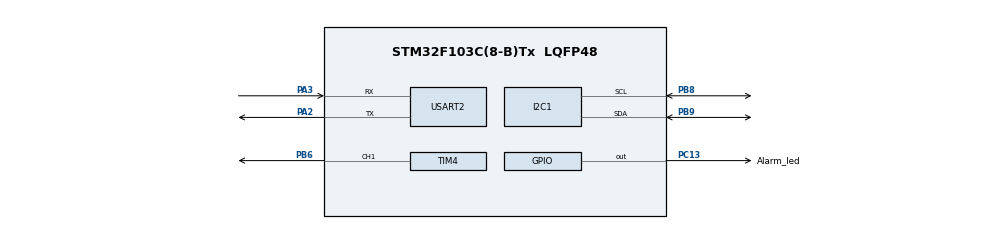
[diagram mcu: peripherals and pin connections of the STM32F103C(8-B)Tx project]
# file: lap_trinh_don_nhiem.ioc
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Dma.Request0=USART2_RX
Dma.USART2_RX.0.Direction=DMA_PERIPH_TO_MEMORY
Dma.USART2_RX.0.Instance=DMA1_Channel6
Dma.USART2_RX.0.MemDataAlignment=DMA_MDATAALIGN_BYTE
Dma.USART2_RX.0.MemInc=DMA_MINC_ENABLE
Dma.USART2_RX.0.Mode=DMA_CIRCULAR
Dma.USART2_RX.0.PeriphDataAlignment=DMA_PDATAALIGN_BYTE
Dma.USART2_RX.0.PeriphInc=DMA_PINC_DISABLE
Dma.USART2_RX.0.Priority=DMA_PRIORITY_LOW
Mcu.Family=STM32F1
Mcu.Name=STM32F103C(8-B)Tx
Mcu.Package=LQFP48
NVIC.DMA1_Channel6_IRQn=true\:0\:0\:false\:false\:true\:false\:true\:true
NVIC.PriorityGroup=NVIC_PRIORITYGROUP_4
PA13.Mode=Serial_Wire
PA13.Signal=SYS_JTMS-SWDIO
PA14.Mode=Serial_Wire
PA14.Signal=SYS_JTCK-SWCLK
PA2.Mode=Asynchronous
PA2.Signal=USART2_TX
PA3.Mode=Asynchronous
PA3.Signal=USART2_RX
PB6.Signal=S_TIM4_CH1
PB8.Mode=I2C
PB8.Signal=I2C1_SCL
PB9.Mode=I2C
PB9.Signal=I2C1_SDA
PC13-TAMPER-RTC.GPIO_Label=Alarm_led
PC13-TAMPER-RTC.Signal=GPIO_Output
PD0-OSC_IN.Mode=HSE-External-Oscillator
PD0-OSC_IN.Signal=RCC_OSC_IN
PD1-OSC_OUT.Mode=HSE-External-Oscillator
PD1-OSC_OUT.Signal=RCC_OSC_OUT
ProjectManager.HeapSize=0x200
ProjectManager.StackSize=0x400
ProjectManager.TargetToolchain=MDK-ARM V5.32
RCC.AHBFreq_Value=72000000
RCC.APB1CLKDivider=RCC_HCLK_DIV2
RCC.APB1Freq_Value=36000000
RCC.APB1TimFreq_Value=72000000
RCC.APB2Freq_Value=72000000
RCC.APB2TimFreq_Value=72000000
RCC.HCLKFreq_Value=72000000
RCC.PLLMUL=RCC_PLL_MUL9
RCC.PLLSourceVirtual=RCC_PLLSOURCE_HSE
RCC.SYSCLKFreq_VALUE=72000000
RCC.SYSCLKSource=RCC_SYSCLKSOURCE_PLLCLK
RCC.USBFreq_Value=72000000
SH.S_TIM4_CH1.0=TIM4_CH1,PWM Generation1 CH1
TIM4.Channel-PWM\ Generation1\ CH1=TIM_CHANNEL_1
TIM4.Period=19999
TIM4.Prescaler=71
USART2.VirtualMode=VM_ASYNC
board=custom

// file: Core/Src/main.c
/* USER CODE BEGIN Header */
/**
  ******************************************************************************
  * @file           : main.c
  * @brief          : Main program body
  ******************************************************************************
  * @attention
  *
  * Copyright (c) 2023 STMicroelectronics.
  * All rights reserved.
  *
  * This software is licensed under terms that can be found in the LICENSE file
  * in the root directory of this software component.
  * If no LICENSE file comes with this software, it is provided AS-IS.
  *
  ******************************************************************************
  */
/* USER CODE END Header */
#include "main.h"

/* USER CODE BEGIN Includes */
#include "ds18b20.h"
#include "sg90.h"
#include "i2c-lcd.h"
#include "uart.h"
#include "timer.h"
/* USER CODE END Includes */

/* USER CODE BEGIN PV */
uint8_t rxBuff[BF_SIZE];

int8_t ex_strlen;

uint16_t pwm_value, pwm_value_pre;
float temp = 0;
bool check = true;
bool alarm_change = false;

int i = 0;
uint8_t alarm_temp = 20;
/* USER CODE END PV */

int main(void)
{
  /* MCU Configuration--------------------------------------------------------*/

  /* Reset of all peripherals, Initializes the Flash interface and the Systick. */
  HAL_Init();
  /* Configure the system clock */
  SystemClock_Config();
  /* Initialize all configured peripherals */
  MX_GPIO_Init();
  MX_DMA_Init();
  MX_I2C1_Init();
  MX_TIM4_Init();
  MX_USART2_UART_Init();
  /* USER CODE BEGIN 2 */
  lcd_init();
  /* USER CODE END 2 */

  /* Infinite loop */
  while (1)
  {
		read_temp_ds18b20(&temp);
		lcd_display_temp();
		RX_handle();
		change_sg90();
		change_alarm();
		set_alarm_led();
		HAL_Delay(100);
  }
}

void Error_Handler(void)
{
  __disable_irq();
  while (1)
  {
  }
}
